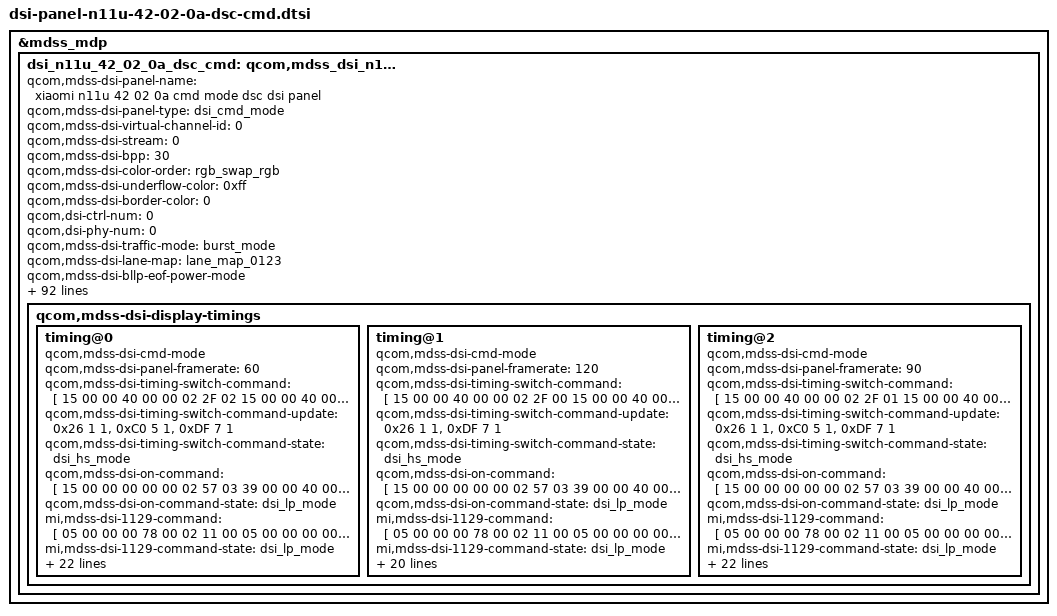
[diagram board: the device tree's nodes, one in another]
/* Panel Attention
 * 1.CCh must be 00 before 51h/26h/38h/39h/gamma change
 */
&mdss_mdp {
	dsi_n11u_42_02_0a_dsc_cmd: qcom,mdss_dsi_n11u_42_02_0a_dsc_cmd {
		qcom,mdss-dsi-panel-name = "xiaomi n11u 42 02 0a cmd mode dsc dsi panel";
		qcom,mdss-dsi-panel-type = "dsi_cmd_mode";
		qcom,mdss-dsi-virtual-channel-id = <0>;
		qcom,mdss-dsi-stream = <0>;
		qcom,mdss-dsi-bpp = <30>;
		qcom,mdss-dsi-color-order = "rgb_swap_rgb";
		qcom,mdss-dsi-underflow-color = <0xff>;
		qcom,mdss-dsi-border-color = <0>;
		qcom,dsi-ctrl-num = <0>;
		qcom,dsi-phy-num = <0>;

		qcom,mdss-dsi-traffic-mode = "burst_mode";
		qcom,mdss-dsi-lane-map = "lane_map_0123";
		qcom,mdss-dsi-bllp-eof-power-mode;
		qcom,mdss-dsi-bllp-power-mode;
		qcom,mdss-dsi-lane-0-state;
		qcom,mdss-dsi-lane-1-state;
		qcom,mdss-dsi-lane-2-state;
		qcom,mdss-dsi-lane-3-state;
		qcom,mdss-dsi-dma-trigger = "trigger_sw";
		qcom,mdss-dsi-mdp-trigger = "none";
		qcom,mdss-dsi-reset-sequence = <1 11>, <0 1>, <1 11>;
		qcom,mdss-pan-physical-width-dimension = <695>;
		qcom,mdss-pan-physical-height-dimension = <1545>;
		qcom,mdss-dsi-te-pin-select = <1>;
		qcom,mdss-dsi-wr-mem-start = <0x2c>;
		qcom,mdss-dsi-wr-mem-continue = <0x3c>;
		qcom,mdss-dsi-te-dcs-command = <1>;
		qcom,mdss-dsi-te-check-enable;
		qcom,mdss-dsi-te-using-te-pin;
		qcom,mdss-dsi-tx-eot-append;
		qcom,mdss-dsi-lp11-init;

		qcom,mdss-dsi-bl-inverted-dbv;
		qcom,bl-update-flag = "delay_until_first_frame";

		qcom,mdss-dsi-panel-hdr-enabled;
		qcom,mdss-dsi-panel-hdr-color-primaries = <14500 15500 32000
			17000 15500 30000 8000 3000>;
		qcom,mdss-dsi-panel-peak-brightness = <12000000>;
		qcom,mdss-dsi-panel-blackness-level = <3230>;

		qcom,mdss-dsi-dma-schedule-line = <1>;
		qcom,mdss-dsi-dma-schedule-window = <50>;

		/* IRQF_ONESHOT | IRQF_TRIGGER_LOW */
		mi,esd-err-irq-gpio = <&tlmm 87 0x2008>;
		mi,panel-id = <0x4E313155 0x00420200>;

		qcom,spr-pack-type = "pentile";
		mi,panel-3840pwm-dbv-threshold = <98>;

		mi,local-hbm-enabled;
		mi,local-hbm-ui-ready-delay-num-frame = <4>; /* 4 frame */
		mi,fod-low-brightness-clone-threshold = <200>;
		mi,fod-low-brightness-lux-threshold = <3>;
		mi,need-fod-animal-in-normal-enabled;

		mi,doze-hbm-dbv-level = <252>;
		mi,doze-lbm-dbv-level = <25>;
		mi,max-brightness-clone = <16383>;

		mi,mdss-dsi-fac-bl-max-level = <2866>;
		mi,mdss-fac-brightness-max-level = <2866>;
		mi,panel-on-dimming-delay = <120>;

		mi,flatmode-default-on-enabled;

		mi,flatmode-status-check-enabled;
		mi,mdss-dsi-panel-flatmode-status-command = [
			06 01 00 01 00 00 01 5F
		];
		mi,mdss-dsi-panel-flatmode-status-command-state = "dsi_lp_mode";
		mi,mdss-dsi-panel-flatmode-status-read-length = <1>;
		mi,mdss-dsi-panel-flatmode-on-status-value = <0x00>;

		mi,mdss-dsi-panel-wp-read-command = [06 01 00 01 00 00 01 A3];
		mi,mdss-dsi-panel-wp-read-command-state = "dsi_lp_mode";
		mi,mdss-dsi-panel-wp-read-length = <8>;

		mi,mdss-dsi-panel-cell-id-read-command = [06 01 00 01 00 00 01 B1];
		mi,mdss-dsi-panel-cell-id-read-pre-tx-command = [
			39 00 00 40 00 00 06 F0 55 AA 52 08 00
			15 00 00 40 00 00 02 EA 10
			39 00 00 00 00 00 06 F0 55 AA 52 00 00
		];
		mi,mdss-dsi-panel-cell-id-read-after-tx-command = [
			39 00 00 40 00 00 06 F0 55 AA 52 08 00
			15 00 00 00 00 00 02 EA 00
		];
		mi,mdss-dsi-panel-cell-id-read-pre-tx-command-state = "dsi_hs_mode";
		mi,mdss-dsi-panel-cell-id-read-after-tx-command-state = "dsi_hs_mode";
		mi,mdss-dsi-panel-cell-id-read-command-state = "dsi_hs_mode";
		mi,mdss-dsi-panel-cell-id-read-length = <13>;

		qcom,mdss-dsi-display-timings {
			/* 60 Hz */
			timing@0 {
				#include "dsi-panel-n11u-42-02-0a-dsc-cmd-common.dtsi"
				#include "dsi-panel-n11u-42-02-0a-dsc-cmd-dbi-bwg-60hz.dtsi"
				qcom,mdss-dsi-cmd-mode;
				qcom,mdss-dsi-panel-framerate = <60>;

				qcom,mdss-dsi-timing-switch-command = [
					/* 60 Hz cmd_1 */
					15 00 00 40 00 00 02 2F 02
					15 00 00 40 00 00 02 26 02
					15 00 00 40 00 00 02 8B 00
					39 00 00 40 00 00 06 F0 55 AA 52 08 00
					15 00 00 40 00 00 02 6F 03
					15 00 00 40 00 00 02 C0 10
					15 00 00 40 00 00 02 6F 31
					15 00 00 40 00 00 02 DF 21
					39 00 00 40 00 00 06 F0 55 AA 52 08 02
					15 00 00 40 00 00 02 CC 30
					15 00 00 00 00 00 02 CE 01
				];
				qcom,mdss-dsi-timing-switch-command-update = <0x26 1 1>, <0xC0 5 1>, <0xDF 7 1>;
				qcom,mdss-dsi-timing-switch-command-state = "dsi_hs_mode";

				qcom,mdss-dsi-on-command = [
					/* Close 3D-LUT */
					15 00 00 00 00 00 02 57 03
					/* DBI Initial Setting */
					39 00 00 40 00 00 06 F0 55 AA 52 08 08
					39 00 00 40 00 00 06 C2 22 80 3B 01 81
					15 00 00 40 00 00 02 C7 13
					39 00 00 40 00 00 0F CB 00 00 00 00 00 00 00 00 00 00 00 00 00 00
					39 00 00 40 00 00 0F CC 00 00 00 00 00 00 00 00 00 00 00 00 00 00
					39 00 00 40 00 00 0F CE 00 00 00 00 00 00 00 00 00 00 00 00 00 00
					39 00 00 40 00 00 03 D3 80 01
					15 00 00 40 00 00 02 6F 02
					39 00 00 40 00 00 06 D3 10 00 B4 00 90
					15 00 00 40 00 00 02 6F 07
					39 00 00 00 00 00 05 D3 80 40 80 80
					/* Close SSD */
					39 00 00 40 00 00 06 F0 55 AA 52 08 00
					15 00 00 40 00 00 02 6F 1A
					15 00 00 00 00 00 02 B5 16
					/* DDIC spr bypass */
					39 00 00 40 00 00 06 F0 55 AA 52 08 03
					15 00 00 40 00 00 02 6F 08
					15 00 00 40 00 00 02 DE 00
					15 00 00 40 00 00 02 6F 09
					39 00 00 40 00 00 07 DE 10 34 25 30 14 25
					39 00 00 40 00 00 06 F0 55 AA 52 08 07
					15 00 00 40 00 00 02 B0 04
					39 00 00 00 00 00 07 B1 60 60 00 60 60 00
					/* LHBM For AP SPR IN*/
					39 00 00 40 00 00 06 F0 55 AA 52 08 07
					39 00 00 40 00 00 12 C0 00 01 08 AA AA AA AA 55 AA AA AA AA AA AA AA AA AA
					39 00 00 40 00 00 06 F0 55 AA 52 08 08
					15 00 00 40 00 00 02 BF 21
					15 00 00 40 00 00 02 6F 0C
					39 00 00 40 00 00 09 BF 00 00 00 00 00 00 00 00
					15 00 00 40 00 00 02 6F 14
					39 00 00 00 00 00 09 BF 00 00 00 00 00 00 00 00
					/* Source SOE control */
					39 00 00 40 00 00 06 F0 55 AA 52 08 00
					15 00 00 40 00 00 02 6F 1A
					15 00 00 00 00 00 02 C2 00
					/* Optimize Ocut stripes */
					39 00 00 40 00 00 06 F0 55 AA 52 08 01
					15 00 00 40 00 00 02 6F 0E
					15 00 00 40 00 00 02 B4 1F
					39 00 00 40 00 00 05 FF AA 55 A5 80
					15 00 00 40 00 00 02 6F 02
					15 00 00 00 00 00 02 F5 10
					/* Optimize rolling water ripple */
					39 00 00 40 00 00 06 F0 55 AA 52 08 01
					15 00 00 40 00 00 02 6F 01
					15 00 00 40 00 00 02 C4 E3
					39 00 00 40 00 00 05 FF AA 55 A5 80
					15 00 00 40 00 00 02 6F 18
					15 00 00 00 00 00 02 F8 19
					/* DVDD strong */
					39 00 00 40 00 00 06 F0 55 AA 52 08 01
					15 00 00 40 00 00 02 6F 01
					39 00 00 00 00 00 04 C5 0B 0B 0B
					/* Source OP Strong */
					39 00 00 40 00 00 06 F0 55 AA 52 08 00
					15 00 00 40 00 00 02 6F 20
					39 00 00 40 00 00 09 C6 55 55 55 55 55 55 55 55
					39 00 00 40 00 00 05 FF AA 55 A5 80
					15 00 00 40 00 00 02 6F 1B
					15 00 00 00 00 00 02 F4 55
					/* SRE optimize for IDLE */
					15 00 00 40 00 00 02 6F 19
					15 00 00 00 00 00 02 F2 00
					/* SDC clk setting */
					39 00 00 40 00 00 05 FF AA 55 A5 81
					15 00 00 40 00 00 02 6F 18
					15 00 00 00 00 00 02 FB 04
					/* skip mode source chopper setting */
					39 00 00 40 00 00 05 FF AA 55 A5 81
					15 00 00 40 00 00 02 6F 07
					15 00 00 00 00 00 02 FC 08
					/* CASET/RASET Setting 1440*3200 */
					39 00 00 40 00 00 05 2A 00 00 05 9F
					39 00 00 00 00 00 05 2B 00 00 0C 7F
					/* DSC Setting */
					15 00 00 40 00 00 02 90 03
					39 00 00 00 00 00 13 91
						AB F0 00 14 D1 00 01 DE 00 A3 00 3C 05 7A 15 9A
						11 50
					/* TE ON */
					15 00 00 40 00 00 02 35 00
					15 00 00 00 00 00 02 5A 01
					/* VPorch-Ext Video */
					39 00 00 00 00 00 05 3B 00 18 00 10
					/* Backlight On */
					15 00 00 00 00 00 02 53 20
					39 00 00 00 00 00 07 51 00 00 00 00 0F FF
					15 00 00 00 00 00 02 9C 01
					15 00 00 00 00 00 02 2C 00
					/* 60Hz GIR ON*/
					15 00 00 40 00 00 02 2F 02
					15 00 00 40 00 00 02 5F 00
					15 00 00 40 00 00 02 26 02
					15 00 00 40 00 00 02 8B 00
					39 00 00 40 00 00 06 F0 55 AA 52 08 00
					15 00 00 40 00 00 02 6F 03
					39 00 00 40 00 00 02 C0 10
					15 00 00 40 00 00 02 6F 31
					15 00 00 40 00 00 02 DF 21
					39 00 00 40 00 00 06 F0 55 AA 52 08 02
					15 00 00 40 00 00 02 CC 30
					15 00 00 00 14 00 02 CE 01
					15 00 00 00 00 00 02 CC 00
					/* video trim */
					39 00 00 40 00 00 06 F0 55 AA 52 08 01
					39 00 00 40 00 00 0C C3 90 04 20 13 FF 00 04 20 0E FF 00
					15 00 00 00 00 00 02 6F 0B
					39 00 00 40 00 00 07 C3 06 38 1D 06 58 17
					15 00 00 00 00 00 02 6F 11
					39 00 00 40 00 00 07 C3 06 45 1D 06 41 16
					15 00 00 00 00 00 02 6F 17
					39 00 00 40 00 00 07 C3 06 38 1D 06 58 17
					15 00 00 00 00 00 02 6F 1D
					39 00 00 40 00 00 07 C3 06 38 1D 06 41 16
					15 00 00 00 00 00 02 6F 23
					39 00 00 40 00 00 07 C3 06 38 1D 06 58 17
					/* ESD Error Flag, Normal High, Error Low */
					39 00 00 40 00 00 06 F0 55 AA 52 08 00
					15 00 00 40 00 00 02 6F 01
					15 00 00 40 00 00 02 BE 45
					15 00 00 40 00 00 02 6F 05
					15 00 00 00 00 00 02 BE 88
					/* aod remove black frame */
					39 00 00 40 00 00 06 F0 55 AA 52 08 00
					15 00 00 40 00 00 02 6F 1A
					15 00 00 40 00 00 02 B5 16
					15 00 00 40 00 00 02 6F 02
					15 00 00 40 00 00 02 B5 15
					15 00 00 40 00 00 02 6F 23
					15 00 00 40 00 00 02 B5 15
					39 00 00 40 00 00 06 F0 55 AA 52 08 01
					39 00 00 40 00 00 06 D2 00 00 00 01 20
					15 00 00 40 00 00 02 6F 05
					39 00 00 40 00 00 04 D2 01 01 00
					15 00 00 40 00 00 02 6F 0E
					39 00 00 40 00 00 06 D2 03 00 10 03 E4
					39 00 00 40 00 00 0B E4 80 03 00 00 00 00 00 00 00 33
					15 00 00 40 00 00 02 6F 0A
					39 00 00 40 00 00 07 E4 80 03 00 10 00 53
					15 00 00 40 00 00 02 6F 03
					15 00 00 40 00 00 02 D8 00
					15 00 00 40 00 00 02 6F 09
					15 00 00 40 00 00 02 D8 00
					15 00 00 40 00 00 02 6F 0F
					15 00 00 00 00 00 02 D8 00
					/* Lv detc */
					39 00 00 40 00 00 06 F0 55 AA 52 08 01
					15 00 00 40 00 00 02 6F 03
					15 00 00 00 00 00 02 C7 37
				];
				qcom,mdss-dsi-on-command-state = "dsi_lp_mode";

				mi,mdss-dsi-1129-command = [
					/* Sleep Out */
					05 00 00 00 78 00 02 11 00
					/* Display On */
					05 00 00 00 00 00 02 29 00
				];
				mi,mdss-dsi-1129-command-state = "dsi_lp_mode";
			};

			/* 120 Hz */
			timing@1 {
				#include "dsi-panel-n11u-42-02-0a-dsc-cmd-common.dtsi"
				#include "dsi-panel-n11u-42-02-0a-dsc-cmd-dbi-bwg-120hz.dtsi"
				qcom,mdss-dsi-cmd-mode;
				qcom,mdss-dsi-panel-framerate = <120>;

				qcom,mdss-dsi-timing-switch-command = [
					/* 120 Hz cmd_1 */
					15 00 00 40 00 00 02 2F 00
					15 00 00 40 00 00 02 26 00
					15 00 00 40 00 00 02 8B 00
					39 00 00 40 00 00 06 F0 55 AA 52 08 00
					15 00 00 40 00 00 02 6F 03
					15 00 00 40 00 00 02 C0 10
					15 00 00 40 00 00 02 6F 31
					15 00 00 40 00 00 02 DF 20
					39 00 00 40 00 00 06 F0 55 AA 52 08 02
					15 00 00 40 00 00 02 CC 30
					15 00 00 00 00 00 02 CE 01
				];
				qcom,mdss-dsi-timing-switch-command-update = <0x26 1 1>, <0xDF 7 1>;
				qcom,mdss-dsi-timing-switch-command-state = "dsi_hs_mode";

				qcom,mdss-dsi-on-command = [
					/* Close 3D-LUT */
					15 00 00 00 00 00 02 57 03
					/* DBI Initial Setting */
					39 00 00 40 00 00 06 F0 55 AA 52 08 08
					39 00 00 40 00 00 06 C2 22 80 3B 01 81
					15 00 00 40 00 00 02 C7 13
					39 00 00 40 00 00 0F CB 00 00 00 00 00 00 00 00 00 00 00 00 00 00
					39 00 00 40 00 00 0F CC 00 00 00 00 00 00 00 00 00 00 00 00 00 00
					39 00 00 40 00 00 0F CE 00 00 00 00 00 00 00 00 00 00 00 00 00 00
					39 00 00 40 00 00 03 D3 80 01
					15 00 00 40 00 00 02 6F 02
					39 00 00 40 00 00 06 D3 10 00 B4 00 90
					15 00 00 40 00 00 02 6F 07
					39 00 00 00 00 00 05 D3 80 40 80 80
					/* Close SSD */
					39 00 00 40 00 00 06 F0 55 AA 52 08 00
					15 00 00 40 00 00 02 6F 1A
					15 00 00 00 00 00 02 B5 16
					/* DDIC spr bypass */
					39 00 00 40 00 00 06 F0 55 AA 52 08 03
					15 00 00 40 00 00 02 6F 08
					15 00 00 40 00 00 02 DE 00
					15 00 00 40 00 00 02 6F 09
					39 00 00 40 00 00 07 DE 10 34 25 30 14 25
					39 00 00 40 00 00 06 F0 55 AA 52 08 07
					15 00 00 40 00 00 02 B0 04
					39 00 00 00 00 00 07 B1 60 60 00 60 60 00
					/* LHBM For AP SPR IN*/
					39 00 00 40 00 00 06 F0 55 AA 52 08 07
					39 00 00 40 00 00 12 C0 00 01 08 AA AA AA AA 55 AA AA AA AA AA AA AA AA AA
					39 00 00 40 00 00 06 F0 55 AA 52 08 08
					15 00 00 40 00 00 02 BF 21
					15 00 00 40 00 00 02 6F 0C
					39 00 00 40 00 00 09 BF 00 00 00 00 00 00 00 00
					15 00 00 40 00 00 02 6F 14
					39 00 00 00 00 00 09 BF 00 00 00 00 00 00 00 00
					/* Source SOE control */
					39 00 00 40 00 00 06 F0 55 AA 52 08 00
					15 00 00 40 00 00 02 6F 1A
					15 00 00 00 00 00 02 C2 00
					/* Optimize Ocut stripes */
					39 00 00 40 00 00 06 F0 55 AA 52 08 01
					15 00 00 40 00 00 02 6F 0E
					15 00 00 40 00 00 02 B4 1F
					39 00 00 40 00 00 05 FF AA 55 A5 80
					15 00 00 40 00 00 02 6F 02
					15 00 00 00 00 00 02 F5 10
					/* Optimize rolling water ripple */
					39 00 00 40 00 00 06 F0 55 AA 52 08 01
					15 00 00 40 00 00 02 6F 01
					15 00 00 40 00 00 02 C4 E3
					39 00 00 40 00 00 05 FF AA 55 A5 80
					15 00 00 40 00 00 02 6F 18
					15 00 00 00 00 00 02 F8 19
					/* DVDD strong */
					39 00 00 40 00 00 06 F0 55 AA 52 08 01
					15 00 00 40 00 00 02 6F 01
					39 00 00 00 00 00 04 C5 0B 0B 0B
					/* Source OP Strong */
					39 00 00 40 00 00 06 F0 55 AA 52 08 00
					15 00 00 40 00 00 02 6F 20
					39 00 00 40 00 00 09 C6 55 55 55 55 55 55 55 55
					39 00 00 40 00 00 05 FF AA 55 A5 80
					15 00 00 40 00 00 02 6F 1B
					15 00 00 00 00 00 02 F4 55
					/* SRE optimize for IDLE */
					15 00 00 40 00 00 02 6F 19
					15 00 00 00 00 00 02 F2 00
					/* SDC clk setting */
					39 00 00 40 00 00 05 FF AA 55 A5 81
					15 00 00 40 00 00 02 6F 18
					15 00 00 00 00 00 02 FB 04
					/* skip mode source chopper setting */
					39 00 00 40 00 00 05 FF AA 55 A5 81
					15 00 00 40 00 00 02 6F 07
					15 00 00 00 00 00 02 FC 08
					/* CASET/RASET Setting 1440*3200 */
					39 00 00 40 00 00 05 2A 00 00 05 9F
					39 00 00 00 00 00 05 2B 00 00 0C 7F
					/* DSC Setting */
					15 00 00 40 00 00 02 90 03
					39 00 00 00 00 00 13 91
						AB F0 00 14 D1 00 01 DE 00 A3 00 3C 05 7A 15 9A
						11 50
					/* TE ON */
					15 00 00 40 00 00 02 35 00
					15 00 00 00 00 00 02 5A 01
					/* VPorch-Ext Video */
					39 00 00 00 00 00 05 3B 00 18 00 10
					/* Backlight On */
					15 00 00 00 00 00 02 53 20
					39 00 00 00 00 00 07 51 00 00 00 00 0F FF
					15 00 00 00 00 00 02 9C 01
					15 00 00 00 00 00 02 2C 00
					/* 120Hz GIR ON*/
					15 00 00 40 00 00 02 2F 00
					15 00 00 40 00 00 02 5F 00
					15 00 00 40 00 00 02 26 00
					15 00 00 40 00 00 02 8B 00
					39 00 00 40 00 00 06 F0 55 AA 52 08 00
					15 00 00 40 00 00 02 6F 03
					39 00 00 40 00 00 02 C0 10
					15 00 00 40 00 00 02 6F 31
					15 00 00 40 00 00 02 DF 20
					39 00 00 40 00 00 06 F0 55 AA 52 08 02
					15 00 00 40 00 00 02 CC 30
					15 00 00 00 14 00 02 CE 01
					15 00 00 00 00 00 02 CC 00
					/* video trim */
					39 00 00 40 00 00 06 F0 55 AA 52 08 01
					39 00 00 40 00 00 0C C3 90 04 20 13 FF 00 04 20 0E FF 00
					15 00 00 00 00 00 02 6F 0B
					39 00 00 40 00 00 07 C3 06 38 1D 06 58 17
					15 00 00 00 00 00 02 6F 11
					39 00 00 40 00 00 07 C3 06 45 1D 06 41 16
					15 00 00 00 00 00 02 6F 17
					39 00 00 40 00 00 07 C3 06 38 1D 06 58 17
					15 00 00 00 00 00 02 6F 1D
					39 00 00 40 00 00 07 C3 06 38 1D 06 41 16
					15 00 00 00 00 00 02 6F 23
					39 00 00 40 00 00 07 C3 06 38 1D 06 58 17
					/* ESD Error Flag, Normal High, Error Low */
					39 00 00 40 00 00 06 F0 55 AA 52 08 00
					15 00 00 40 00 00 02 6F 01
					15 00 00 40 00 00 02 BE 45
					15 00 00 40 00 00 02 6F 05
					15 00 00 00 00 00 02 BE 88
					/* aod remove black frame */
					39 00 00 40 00 00 06 F0 55 AA 52 08 00
					15 00 00 40 00 00 02 6F 1A
					15 00 00 40 00 00 02 B5 16
					15 00 00 40 00 00 02 6F 02
					15 00 00 40 00 00 02 B5 15
					15 00 00 40 00 00 02 6F 23
					15 00 00 40 00 00 02 B5 15
					39 00 00 40 00 00 06 F0 55 AA 52 08 01
					39 00 00 40 00 00 06 D2 00 00 00 01 20
					15 00 00 40 00 00 02 6F 05
					39 00 00 40 00 00 04 D2 01 01 00
					15 00 00 40 00 00 02 6F 0E
					39 00 00 40 00 00 06 D2 03 00 10 03 E4
					39 00 00 40 00 00 0B E4 80 03 00 00 00 00 00 00 00 33
					15 00 00 40 00 00 02 6F 0A
					39 00 00 40 00 00 07 E4 80 03 00 10 00 53
					15 00 00 40 00 00 02 6F 03
					15 00 00 40 00 00 02 D8 00
					15 00 00 40 00 00 02 6F 09
					15 00 00 40 00 00 02 D8 00
					15 00 00 40 00 00 02 6F 0F
					15 00 00 00 00 00 02 D8 00
				];
				qcom,mdss-dsi-on-command-state = "dsi_lp_mode";

				mi,mdss-dsi-1129-command = [
					/* Sleep Out */
					05 00 00 00 78 00 02 11 00
					/* Display On */
					05 00 00 00 00 00 02 29 00
				];
				mi,mdss-dsi-1129-command-state = "dsi_lp_mode";
			};

			/* 90 Hz */
			timing@2 {
				#include "dsi-panel-n11u-42-02-0a-dsc-cmd-common.dtsi"
				#include "dsi-panel-n11u-42-02-0a-dsc-cmd-dbi-bwg-90hz.dtsi"
				qcom,mdss-dsi-cmd-mode;
				qcom,mdss-dsi-panel-framerate = <90>;

				qcom,mdss-dsi-timing-switch-command = [
					/* 90 Hz cmd_1 */
					15 00 00 40 00 00 02 2F 01
					15 00 00 40 00 00 02 26 02
					15 00 00 40 00 00 02 8B 10
					39 00 00 40 00 00 06 F0 55 AA 52 08 00
					15 00 00 40 00 00 02 6F 03
					15 00 00 40 00 00 02 C0 10
					15 00 00 40 00 00 02 6F 31
					15 00 00 40 00 00 02 DF 20
					39 00 00 40 00 00 06 F0 55 AA 52 08 02
					15 00 00 40 00 00 02 CC 30
					15 00 00 00 00 00 02 CE 01
				];
				qcom,mdss-dsi-timing-switch-command-update = <0x26 1 1>, <0xC0 5 1>, <0xDF 7 1>;
				qcom,mdss-dsi-timing-switch-command-state = "dsi_hs_mode";

				qcom,mdss-dsi-on-command = [
					/* Close 3D-LUT */
					15 00 00 00 00 00 02 57 03
					/* DBI Initial Setting */
					39 00 00 40 00 00 06 F0 55 AA 52 08 08
					39 00 00 40 00 00 06 C2 22 80 3B 01 81
					15 00 00 40 00 00 02 C7 13
					39 00 00 40 00 00 0F CB 00 00 00 00 00 00 00 00 00 00 00 00 00 00
					39 00 00 40 00 00 0F CC 00 00 00 00 00 00 00 00 00 00 00 00 00 00
					39 00 00 40 00 00 0F CE 00 00 00 00 00 00 00 00 00 00 00 00 00 00
					39 00 00 40 00 00 03 D3 80 01
					15 00 00 40 00 00 02 6F 02
					39 00 00 40 00 00 06 D3 10 00 B4 00 90
					15 00 00 40 00 00 02 6F 07
					39 00 00 00 00 00 05 D3 80 40 80 80
					/* Close SSD */
					39 00 00 40 00 00 06 F0 55 AA 52 08 00
					15 00 00 40 00 00 02 6F 1A
					15 00 00 00 00 00 02 B5 16
					/* DDIC spr bypass */
					39 00 00 40 00 00 06 F0 55 AA 52 08 03
					15 00 00 40 00 00 02 6F 08
					15 00 00 40 00 00 02 DE 00
					15 00 00 40 00 00 02 6F 09
					39 00 00 40 00 00 07 DE 10 34 25 30 14 25
					39 00 00 40 00 00 06 F0 55 AA 52 08 07
					15 00 00 40 00 00 02 B0 04
					39 00 00 00 00 00 07 B1 60 60 00 60 60 00
					/* LHBM For AP SPR IN*/
					39 00 00 40 00 00 06 F0 55 AA 52 08 07
					39 00 00 40 00 00 12 C0 00 01 08 AA AA AA AA 55 AA AA AA AA AA AA AA AA AA
					39 00 00 40 00 00 06 F0 55 AA 52 08 08
					15 00 00 40 00 00 02 BF 21
					15 00 00 40 00 00 02 6F 0C
					39 00 00 40 00 00 09 BF 00 00 00 00 00 00 00 00
					15 00 00 40 00 00 02 6F 14
					39 00 00 00 00 00 09 BF 00 00 00 00 00 00 00 00
					/* Source SOE control */
					39 00 00 40 00 00 06 F0 55 AA 52 08 00
					15 00 00 40 00 00 02 6F 1A
					15 00 00 00 00 00 02 C2 00
					/* Optimize Ocut stripes */
					39 00 00 40 00 00 06 F0 55 AA 52 08 01
					15 00 00 40 00 00 02 6F 0E
					15 00 00 40 00 00 02 B4 1F
					39 00 00 40 00 00 05 FF AA 55 A5 80
					15 00 00 40 00 00 02 6F 02
					15 00 00 00 00 00 02 F5 10
					/* Optimize rolling water ripple */
					39 00 00 40 00 00 06 F0 55 AA 52 08 01
					15 00 00 40 00 00 02 6F 01
					15 00 00 40 00 00 02 C4 E3
					39 00 00 40 00 00 05 FF AA 55 A5 80
					15 00 00 40 00 00 02 6F 18
					15 00 00 00 00 00 02 F8 19
					/* DVDD strong */
					39 00 00 40 00 00 06 F0 55 AA 52 08 01
					15 00 00 40 00 00 02 6F 01
					39 00 00 00 00 00 04 C5 0B 0B 0B
					/* Source OP Strong */
					39 00 00 40 00 00 06 F0 55 AA 52 08 00
					15 00 00 40 00 00 02 6F 20
					39 00 00 40 00 00 09 C6 55 55 55 55 55 55 55 55
					39 00 00 40 00 00 05 FF AA 55 A5 80
					15 00 00 40 00 00 02 6F 1B
					15 00 00 00 00 00 02 F4 55
					/* SRE optimize for IDLE */
					15 00 00 40 00 00 02 6F 19
					15 00 00 00 00 00 02 F2 00
					/* SDC clk setting */
					39 00 00 40 00 00 05 FF AA 55 A5 81
					15 00 00 40 00 00 02 6F 18
					15 00 00 00 00 00 02 FB 04
					/* skip mode source chopper setting */
					39 00 00 40 00 00 05 FF AA 55 A5 81
					15 00 00 40 00 00 02 6F 07
					15 00 00 00 00 00 02 FC 08
					/* CASET/RASET Setting 1440*3200 */
					39 00 00 40 00 00 05 2A 00 00 05 9F
					39 00 00 00 00 00 05 2B 00 00 0C 7F
					/* DSC Setting */
					15 00 00 40 00 00 02 90 03
					39 00 00 00 00 00 13 91
						AB F0 00 14 D1 00 01 DE 00 A3 00 3C 05 7A 15 9A
						11 50
					/* TE ON */
					15 00 00 40 00 00 02 35 00
					15 00 00 00 00 00 02 5A 01
					/* VPorch-Ext Video */
					39 00 00 00 00 00 05 3B 00 18 00 10
					/* Backlight On */
					15 00 00 00 00 00 02 53 20
					39 00 00 00 00 00 07 51 00 00 00 00 0F FF
					15 00 00 00 00 00 02 9C 01
					15 00 00 00 00 00 02 2C 00
					/* 90Hz GIR ON*/
					15 00 00 40 00 00 02 2F 01
					15 00 00 40 00 00 02 5F 00
					15 00 00 40 00 00 02 26 02
					15 00 00 40 00 00 02 8B 10
					39 00 00 40 00 00 06 F0 55 AA 52 08 00
					15 00 00 40 00 00 02 6F 03
					39 00 00 40 00 00 02 C0 10
					15 00 00 40 00 00 02 6F 31
					15 00 00 40 00 00 02 DF 20
					39 00 00 40 00 00 06 F0 55 AA 52 08 02
					15 00 00 40 00 00 02 CC 30
					15 00 00 00 14 00 02 CE 01
					15 00 00 00 00 00 02 CC 00
					/* video trim */
					39 00 00 40 00 00 06 F0 55 AA 52 08 01
					39 00 00 40 00 00 0C C3 90 04 20 13 FF 00 04 20 0E FF 00
					15 00 00 00 00 00 02 6F 0B
					39 00 00 40 00 00 07 C3 06 38 1D 06 58 17
					15 00 00 00 00 00 02 6F 11
					39 00 00 40 00 00 07 C3 06 45 1D 06 41 16
					15 00 00 00 00 00 02 6F 17
					39 00 00 40 00 00 07 C3 06 38 1D 06 58 17
					15 00 00 00 00 00 02 6F 1D
					39 00 00 40 00 00 07 C3 06 38 1D 06 41 16
					15 00 00 00 00 00 02 6F 23
					39 00 00 40 00 00 07 C3 06 38 1D 06 58 17
					/* ESD Error Flag, Normal High, Error Low */
					39 00 00 40 00 00 06 F0 55 AA 52 08 00
					15 00 00 40 00 00 02 6F 01
					15 00 00 40 00 00 02 BE 45
					15 00 00 40 00 00 02 6F 05
					15 00 00 00 00 00 02 BE 88
					/* aod remove black frame */
					39 00 00 40 00 00 06 F0 55 AA 52 08 00
					15 00 00 40 00 00 02 6F 1A
					15 00 00 40 00 00 02 B5 16
					15 00 00 40 00 00 02 6F 02
					15 00 00 40 00 00 02 B5 15
					15 00 00 40 00 00 02 6F 23
					15 00 00 40 00 00 02 B5 15
					39 00 00 40 00 00 06 F0 55 AA 52 08 01
					39 00 00 40 00 00 06 D2 00 00 00 01 20
					15 00 00 40 00 00 02 6F 05
					39 00 00 40 00 00 04 D2 01 01 00
					15 00 00 40 00 00 02 6F 0E
					39 00 00 40 00 00 06 D2 03 00 10 03 E4
					39 00 00 40 00 00 0B E4 80 03 00 00 00 00 00 00 00 33
					15 00 00 40 00 00 02 6F 0A
					39 00 00 40 00 00 07 E4 80 03 00 10 00 53
					15 00 00 40 00 00 02 6F 03
					15 00 00 40 00 00 02 D8 00
					15 00 00 40 00 00 02 6F 09
					15 00 00 40 00 00 02 D8 00
					15 00 00 40 00 00 02 6F 0F
					15 00 00 00 00 00 02 D8 00
				];
				qcom,mdss-dsi-on-command-state = "dsi_lp_mode";

				mi,mdss-dsi-1129-command = [
					/* Sleep Out */
					05 00 00 00 78 00 02 11 00
					/* Display On */
					05 00 00 00 00 00 02 29 00
				];
				mi,mdss-dsi-1129-command-state = "dsi_lp_mode";
			};
		};
	};
};

&dsi_n11u_42_02_0a_dsc_cmd {
	qcom,panel-supply-entries = <&dsi_panel_pwr_supply_N11u>;
	qcom,mdss-dsi-bl-pmic-control-type = "bl_ctrl_dcs";
	qcom,mdss-dsi-bl-min-level = <25>;
	qcom,mdss-dsi-bl-max-level = <4095>;
	qcom,bl-dsc-cmd-state = "dsi_hs_mode";
	qcom,mdss-brightness-max-level = <4095>;
	qcom,mdss-brightness-init-level = <307>;
	qcom,platform-reset-gpio = <&tlmm 133 0>;

	mi,panel-build-id-read-needed;
	mi,panel-build-id-read-length = <1>;
	mi,mdss-dsi-panel-build-id-read-command = [06 01 00 01 00 00 01 DA];
	mi,mdss-dsi-panel-build-id-read-command-state = "dsi_lp_mode";

	mi,disable-ic-dimming-flag;
	qcom,mdss-dsi-panel-vsync-delay;
	qcom,ulps-enabled;
	qcom,dsi-select-clocks = "pll_byte_clk0", "pll_dsi_clk0";
	qcom,mdss-dsi-clk-strength = <0xFF>;

	qcom,mdss-dsi-display-timings {
		timing@0{ /* 60 hz */
			/*<flat on gamma, flat off gamma>*/
			mi,mdss-flat-status-control-gamma-26-cfg  = <0x02 0x00>;
			mi,mdss-flat-status-control-gamma-C0-cfg  = <0x10 0x30>;
			mi,mdss-flat-status-control-gamma-DF-cfg  = <0x21 0x23>;

			mi,mdss-dsi-flat-mode-on-command = [
				/* 60hz gir cmd_1 */
				15 00 00 00 00 00 02 2F 02
				15 00 00 60 00 00 02 5F 00
				15 00 00 60 00 00 02 26 02
				15 00 00 60 00 00 02 8B 00
				39 00 00 60 00 00 06 F0 55 AA 52 08 00
				15 00 00 60 00 00 02 6F 03
				39 00 00 60 00 00 02 C0 10
				15 00 00 60 00 00 02 6F 31
				15 00 00 60 00 00 02 DF 21
				39 00 00 60 00 00 06 F0 55 AA 52 08 02
				15 00 00 60 00 00 02 CC 30
				15 00 00 20 14 00 02 CE 01
			];
			mi,mdss-dsi-flat-mode-on-command-state = "dsi_lp_mode";

			mi,mdss-dsi-flat-mode-on-sec-command = [
				/* 60hz gir cmd_2 */
				39 00 00 00 00 00 06 F0 55 AA 52 08 02
				15 00 00 00 00 00 02 CC 00
			];
			mi,mdss-dsi-flat-mode-on-sec-command-state = "dsi_lp_mode";

			mi,mdss-dsi-flat-mode-off-command = [
				/* 60hz gir cmd_1 */
				15 00 00 00 00 00 02 2F 02
				15 00 00 60 00 00 02 5F 01
				15 00 00 60 00 00 02 26 00
				15 00 00 60 00 00 02 8B 00
				39 00 00 60 00 00 06 F0 55 AA 52 08 00
				15 00 00 60 00 00 02 6F 03
				39 00 00 60 00 00 02 C0 30
				15 00 00 60 00 00 02 6F 31
				15 00 00 60 00 00 02 DF 23
				39 00 00 60 00 00 06 F0 55 AA 52 08 02
				15 00 00 60 00 00 02 CC 30
				15 00 00 20 14 00 02 CE 01
			];
			mi,mdss-dsi-flat-mode-off-command-state = "dsi_lp_mode";

			mi,mdss-dsi-flat-mode-off-sec-command = [
				/* 60hz gir cmd_2 */
				39 00 00 00 00 00 06 F0 55 AA 52 08 02
				15 00 00 00 00 00 02 CC 00
			];
			mi,mdss-dsi-flat-mode-off-sec-command-state = "dsi_lp_mode";
		};

		timing@1{ /* 120 hz */
			/*<flat on gamma, flat off gamma>*/
			mi,mdss-flat-status-control-gamma-26-cfg  = <0x00 0x02>;
			mi,mdss-flat-status-control-gamma-DF-cfg  = <0x20 0x22>;

			mi,mdss-dsi-flat-mode-on-command = [
				/* 120hz gir cmd_1 */
				15 00 00 00 00 00 02 2F 00
				15 00 00 60 00 00 02 5F 00
				15 00 00 60 00 00 02 26 00
				15 00 00 60 00 00 02 8B 00
				39 00 00 60 00 00 06 F0 55 AA 52 08 00
				15 00 00 60 00 00 02 6F 03
				39 00 00 60 00 00 02 C0 10
				15 00 00 60 00 00 02 6F 31
				15 00 00 60 00 00 02 DF 20
				39 00 00 60 00 00 06 F0 55 AA 52 08 02
				15 00 00 60 00 00 02 CC 30
				15 00 00 20 14 00 02 CE 01
			];
			mi,mdss-dsi-flat-mode-on-command-state = "dsi_lp_mode";

			mi,mdss-dsi-flat-mode-on-sec-command = [
				/* 120hz gir cmd_2 */
				39 00 00 00 00 00 06 F0 55 AA 52 08 02
				15 00 00 00 00 00 02 CC 00
			];
			mi,mdss-dsi-flat-mode-on-sec-command-state = "dsi_lp_mode";

			mi,mdss-dsi-flat-mode-off-command = [
				/* 120hz gir cmd_1 */
				15 00 00 00 00 00 02 2F 00
				15 00 00 60 00 00 02 5F 01
				15 00 00 60 00 00 02 26 02
				15 00 00 60 00 00 02 8B 00
				39 00 00 60 00 00 06 F0 55 AA 52 08 00
				15 00 00 60 00 00 02 6F 03
				39 00 00 60 00 00 02 C0 10
				15 00 00 60 00 00 02 6F 31
				15 00 00 60 00 00 02 DF 22
				39 00 00 60 00 00 06 F0 55 AA 52 08 02
				15 00 00 60 00 00 02 CC 30
				15 00 00 20 14 00 02 CE 01
			];
			mi,mdss-dsi-flat-mode-off-command-state = "dsi_lp_mode";

			mi,mdss-dsi-flat-mode-off-sec-command = [
				/* 120hz gir cmd_2 */
				39 00 00 00 00 00 06 F0 55 AA 52 08 02
				15 00 00 00 00 00 02 CC 00
			];
			mi,mdss-dsi-flat-mode-off-sec-command-state = "dsi_lp_mode";
		};

		timing@2{ /* 90 hz */
			/*<flat on gamma, flat off gamma>*/
			mi,mdss-flat-status-control-gamma-26-cfg  = <0x02 0x00>;
			mi,mdss-flat-status-control-gamma-C0-cfg  = <0x10 0x12>;
			mi,mdss-flat-status-control-gamma-DF-cfg  = <0x20 0x22>;

			mi,mdss-dsi-flat-mode-on-command = [
				/* 90hz gir cmd_1 */
				15 00 00 00 00 00 02 2F 01
				15 00 00 60 00 00 02 5F 00
				15 00 00 60 00 00 02 26 02
				15 00 00 60 00 00 02 8B 10
				39 00 00 60 00 00 06 F0 55 AA 52 08 00
				15 00 00 60 00 00 02 6F 03
				39 00 00 60 00 00 02 C0 10
				15 00 00 60 00 00 02 6F 31
				15 00 00 60 00 00 02 DF 20
				39 00 00 60 00 00 06 F0 55 AA 52 08 02
				15 00 00 60 00 00 02 CC 30
				15 00 00 20 14 00 02 CE 01
			];
			mi,mdss-dsi-flat-mode-on-command-state = "dsi_lp_mode";

			mi,mdss-dsi-flat-mode-on-sec-command = [
				/* 90hz gir cmd_2 */
				39 00 00 00 00 00 06 F0 55 AA 52 08 02
				15 00 00 00 00 00 02 CC 00
			];
			mi,mdss-dsi-flat-mode-on-sec-command-state = "dsi_lp_mode";

			mi,mdss-dsi-flat-mode-off-command = [
				/* 90hz gir cmd_1 */
				15 00 00 00 00 00 02 2F 01
				15 00 00 60 00 00 02 5F 01
				15 00 00 60 00 00 02 26 00
				15 00 00 60 00 00 02 8B 10
				39 00 00 60 00 00 06 F0 55 AA 52 08 00
				15 00 00 60 00 00 02 6F 03
				39 00 00 60 00 00 02 C0 12
				15 00 00 60 00 00 02 6F 31
				15 00 00 60 00 00 02 DF 22
				39 00 00 60 00 00 06 F0 55 AA 52 08 02
				15 00 00 60 00 00 02 CC 30
				15 00 00 20 14 00 02 CE 01
			];
			mi,mdss-dsi-flat-mode-off-command-state = "dsi_lp_mode";

			mi,mdss-dsi-flat-mode-off-sec-command = [
				/* 90hz gir cmd_2 */
				39 00 00 00 00 00 06 F0 55 AA 52 08 02
				15 00 00 00 00 00 02 CC 00
			];
			mi,mdss-dsi-flat-mode-off-sec-command-state = "dsi_lp_mode";
		};
	};
};

